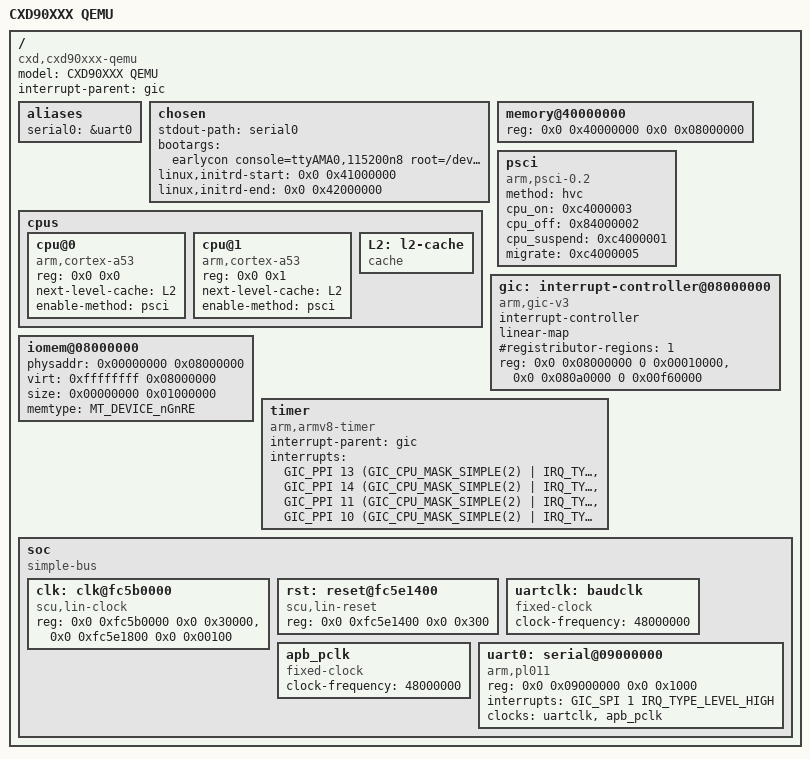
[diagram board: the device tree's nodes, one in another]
/dts-v1/;

#include <dt-bindings/interrupt-controller/arm-gic.h>
#include <dt-bindings/arm/memtype.h>


/ {
	model = "CXD90XXX QEMU";
	compatible = "cxd,cxd90xxx-qemu";

	interrupt-parent = <&gic>;

	#address-cells = <2>;
	#size-cells = <2>;

	aliases {
		serial0 = &uart0;
	};

	chosen {
		stdout-path = "serial0";
		bootargs = "earlycon console=ttyAMA0,115200n8 root=/dev/ram0 ramdisk_size=1024576 rootfstype=ext2 rw noatime init=/sbin/init malloc.debug=1 memrsv=1M@0x40000000 boottime=64K@0x40000000 memrsv=16M@0x43000000:uc heap_profile.records=1000 manage.irqd=129 klog.addr=0x40010000 klog.size=0x10000 tmonitor.addr=0x43000000 tmonitor.size=0x100000 tmonitor.mask=0";
		linux,initrd-start = <0x0 0x41000000>;
		linux,initrd-end   = <0x0 0x42000000>;
	};

	memory@40000000 {
		device_type = "memory";
		reg = <0x0 0x40000000 0x0 0x08000000>;
	};

	psci {
		compatible = "arm,psci-0.2", "arm,psci";
		method = "hvc";

		cpu_on  = < 0xc4000003 >;
		cpu_off = < 0x84000002 >;
		cpu_suspend = < 0xc4000001 >;
		migrate = < 0xc4000005 >;
	};

	cpus {
		#address-cells = <2>;
		#size-cells = <0>;

		cpu@0 {
			device_type = "cpu";
			compatible = "arm,cortex-a53", "arm,armv8";
			reg = <0x0 0x0>;
			next-level-cache = <&L2>;
			enable-method = "psci";
	      	};

		cpu@1 {
			device_type = "cpu";
			compatible = "arm,cortex-a53", "arm,armv8";
			reg = <0x0 0x1>;
			next-level-cache = <&L2>;
			enable-method = "psci";
		};

		L2: l2-cache {
			compatible = "cache";
		};
	};

	gic: interrupt-controller@08000000 {
		compatible = "arm,gic-v3";
		#interrupt-cells = <3>;
		#address-cells = <2>;
		#size-cells = <2>;
		ranges;
		interrupt-controller;
		linear-map;
		#registributor-regions = <1>;
		reg = <0x0 0x08000000 0 0x00010000>, // GICD
		      <0x0 0x080a0000 0 0x00f60000>; // GICR
        };
	iomem@08000000 {
		device_type = "iomap";
		physaddr = <0x00000000 0x08000000>;
		virt     = <0xffffffff 0x08000000>;
		size     = <0x00000000 0x01000000>;
		memtype  = <MT_DEVICE_nGnRE>;
	};

	timer {
		compatible = "arm,armv8-timer";
		interrupt-parent = <&gic>;
		interrupts = <GIC_PPI 13 (GIC_CPU_MASK_SIMPLE(2) | IRQ_TYPE_LEVEL_LOW)>,
			     <GIC_PPI 14 (GIC_CPU_MASK_SIMPLE(2) | IRQ_TYPE_LEVEL_LOW)>,
			     <GIC_PPI 11 (GIC_CPU_MASK_SIMPLE(2) | IRQ_TYPE_LEVEL_LOW)>,
			     <GIC_PPI 10 (GIC_CPU_MASK_SIMPLE(2) | IRQ_TYPE_LEVEL_LOW)>;
	};

	soc {
		compatible = "simple-bus";
		#address-cells = <2>;
		#size-cells = <2>;
		ranges;

		clk: clk@fc5b0000 {
			compatible = "scu,lin-clock";
			reg = <0x0 0xfc5b0000 0x0 0x30000>,
			      <0x0 0xfc5e1800 0x0 0x00100>;
			#clock-cells = <1>;
		};

		rst: reset@fc5e1400 {
			compatible = "scu,lin-reset";
			reg = <0x0 0xfc5e1400 0x0 0x300>;
			#reset-cells = <1>;
		};

		uartclk: baudclk {
			compatible = "fixed-clock";
			#clock-cells = <0>;
			clock-frequency = <48000000>;
		};

		apb_pclk: apb_pclk {
			compatible = "fixed-clock";
			#clock-cells = <0>;
			clock-frequency = <48000000>;
		};

		uart0: serial@09000000 {
			compatible = "arm,pl011", "arm,primecell";
			reg = <0x0 0x09000000 0x0 0x1000>;
			interrupts = <GIC_SPI 1 IRQ_TYPE_LEVEL_HIGH>;
			clocks = <&uartclk>, <&apb_pclk>;
			clock-names = "uartclk", "apb_pclk";
		};
	};
};
